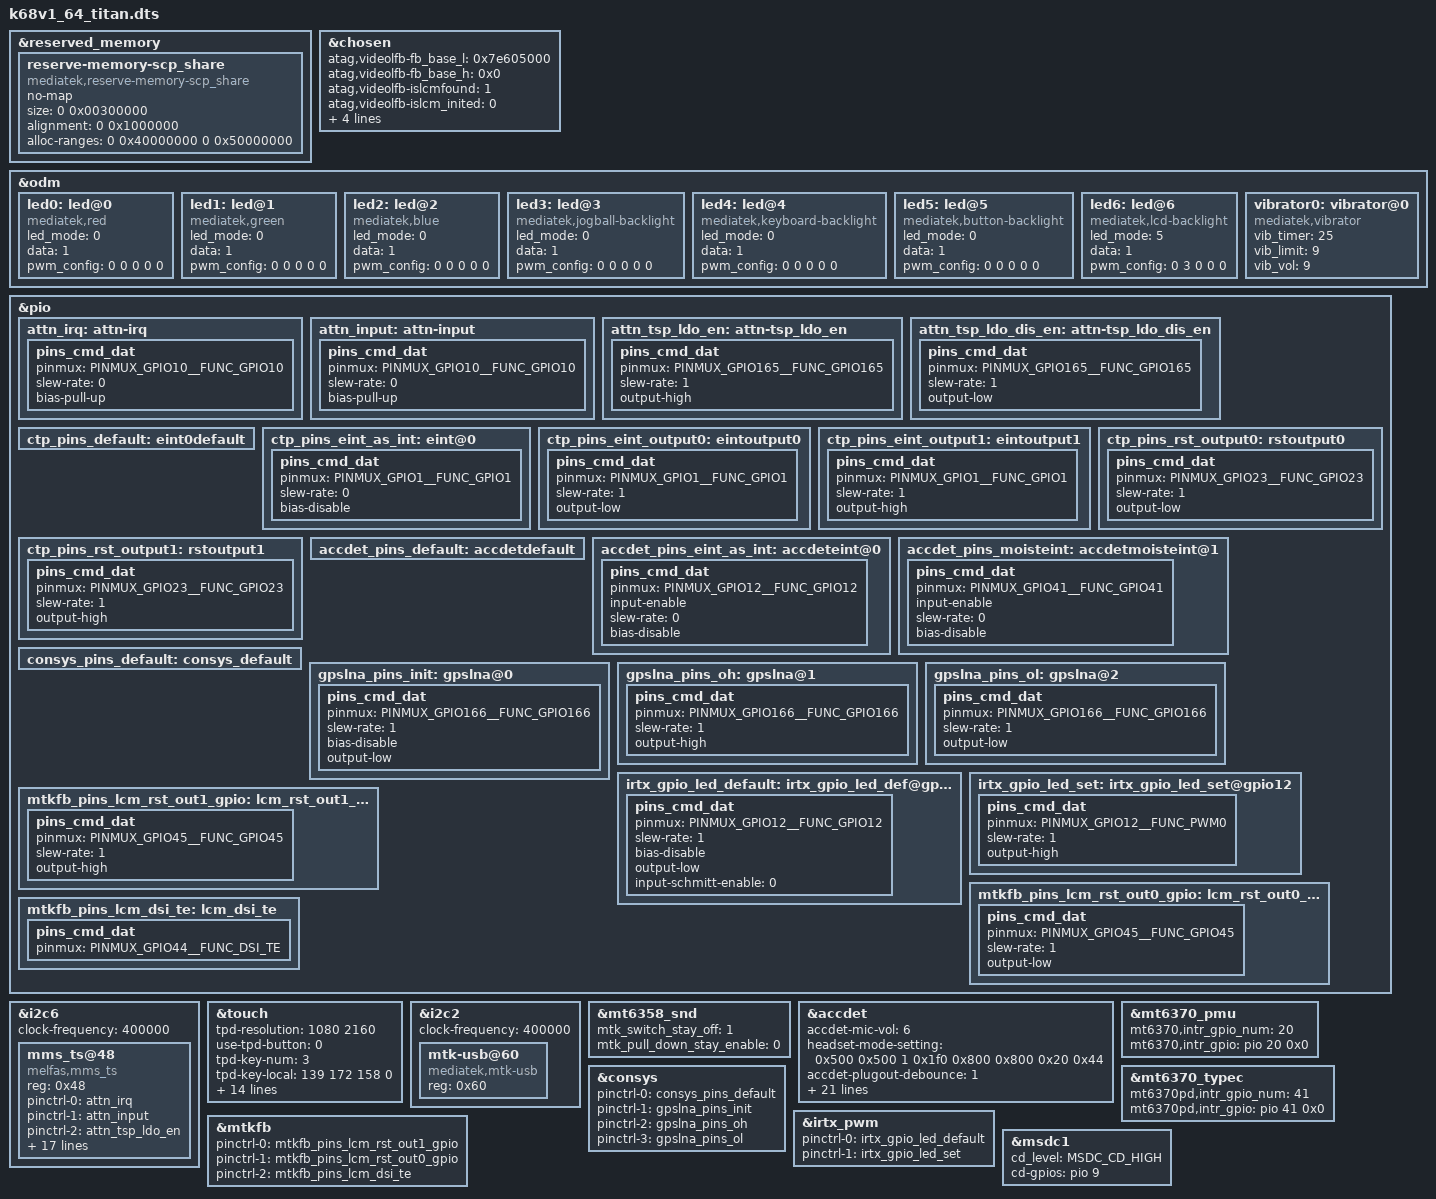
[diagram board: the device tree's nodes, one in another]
/*
 * Copyright (C) 2019 MediaTek Inc.
 *
 * This program is free software; you can redistribute it and/or modify
 * it under the terms of the GNU General Public License version 2 as
 * published by the Free Software Foundation.
 *
 * This program is distributed in the hope that it will be useful,
 * but WITHOUT ANY WARRANTY; without even the implied warranty of
 * MERCHANTABILITY or FITNESS FOR A PARTICULAR PURPOSE.
 * See http://www.gnu.org/licenses/gpl-2.0.html for more details.
 */

#include <dt-bindings/interrupt-controller/irq.h>
#include <dt-bindings/interrupt-controller/arm-gic.h>
#include <dt-bindings/pinctrl/mt6768-pinfunc.h>
#include <dt-bindings/mmc/mt6768-msdc.h>
#include <dt-bindings/gpio/gpio.h>

&reserved_memory {
	reserve-memory-scp_share {
		compatible = "mediatek,reserve-memory-scp_share";
		no-map;
		size = <0 0x00300000>;
		alignment = <0 0x1000000>;
		alloc-ranges = <0 0x40000000 0 0x50000000>;
	};
};

/* chosen */
&chosen {

	atag,videolfb-fb_base_l = <0x7e605000>;
	atag,videolfb-fb_base_h = <0x0>;
	atag,videolfb-islcmfound = <1>;
	atag,videolfb-islcm_inited = <0>;
	atag,videolfb-fps= <6000>;
	atag,videolfb-vramSize= <0x017e8000>;
	atag,videolfb-lcmname=
		"hx83112b_fhdp_dsi_cmd_auo_rt5081_drv";
};

&odm {
	led0:led@0 {
		compatible = "mediatek,red";
		led_mode = <0>;
		data = <1>;
		pwm_config = <0 0 0 0 0>;
	};
	led1:led@1 {
		compatible = "mediatek,green";
		led_mode = <0>;
		data = <1>;
		pwm_config = <0 0 0 0 0>;
	};
	led2:led@2 {
		compatible = "mediatek,blue";
		led_mode = <0>;
		data = <1>;
		pwm_config = <0 0 0 0 0>;
	};
	led3:led@3 {
		compatible = "mediatek,jogball-backlight";
		led_mode = <0>;
		data = <1>;
		pwm_config = <0 0 0 0 0>;
	};
	led4:led@4 {
		compatible = "mediatek,keyboard-backlight";
		led_mode = <0>;
		data = <1>;
		pwm_config = <0 0 0 0 0>;
	};
	led5:led@5 {
		compatible = "mediatek,button-backlight";
		led_mode = <0>;
		data = <1>;
		pwm_config = <0 0 0 0 0>;
	};
	led6:led@6 {
		compatible = "mediatek,lcd-backlight";
		led_mode = <5>;
		data = <1>;
		pwm_config = <0 3 0 0 0>;
	};
	vibrator0:vibrator@0 {
		compatible = "mediatek,vibrator";
		vib_timer = <25>;
		vib_limit = <9>;
		vib_vol= <9>;
	};
};

/* TOUCH start */
/* mms 400 touch */
&pio {
	attn_irq: attn-irq {
		pins_cmd_dat {
			pinmux = <PINMUX_GPIO10__FUNC_GPIO10>;
			slew-rate = <0>;
			bias-pull-up;
			};
	};

	attn_input: attn-input {
		pins_cmd_dat {
			pinmux = <PINMUX_GPIO10__FUNC_GPIO10>;
			slew-rate = <0>;
			bias-pull-up;
		};
	};

	attn_tsp_ldo_en: attn-tsp_ldo_en {
		pins_cmd_dat {
			pinmux = <PINMUX_GPIO165__FUNC_GPIO165>;
			slew-rate = <1>;
			output-high;
		};
	};
	attn_tsp_ldo_dis_en: attn-tsp_ldo_dis_en {
		pins_cmd_dat {
			pinmux = <PINMUX_GPIO165__FUNC_GPIO165>;
			slew-rate = <1>;
			output-low;
		};
	};
};

&i2c6 {
	status = "okay";
	/* samsung,i2c-sda-delay = <100>; */
	/* samsung,i2c-max-bus-freq = <400000>; */
	clock-frequency = <400000>;
	#address-cells = <1>;
	#size-cells = <0>;
	mms_ts@48 {
		compatible = "melfas,mms_ts";
		reg = <0x48>;
		pinctrl-names = "on_state", "off_state",
				"tsp_ldo_en", "tsp_ldo_dis_en";
		pinctrl-0 = <&attn_irq>;
		pinctrl-1 = <&attn_input>;
		pinctrl-2 = <&attn_tsp_ldo_en>;
		pinctrl-3 = <&attn_tsp_ldo_dis_en>;
		/* melfas,vdd_en = "tsp_ldo_en"; */
		/* melfas,io_en = "tsp_io"; */
		melfas,irq-gpio = <&pio 10 0>;
		melfas,scl-gpio = <&pio 89 0>;
		melfas,sda-gpio = <&pio 90 0>;
		/* indicator: 24dp navigator:48dp edge:60px dpi=320 */
		melfas,area-size = <133 266 341>;
		/* x & y */
		melfas,max_x_y = <4095 4095>;
		melfas,node_info = <15 32 0>;
		melfas,event_info = <8 12>;
		melfas,fod_info = <15 14 27>;
		melfas,support_lpm = "true";
		melfas,fw_name = "tsp_melfas/mss100_a50.fw";
		melfas,fw_name_old = "tsp_melfas/mss100_a50_p01.fw";
		melfas,project_name = "A505";
		support_ear_detect_mode;
		enable_settings_aot;
		support_fod;
	};
};

&touch {
	tpd-resolution = <1080 2160>;
	use-tpd-button = <0>;
	tpd-key-num = <3>;
	tpd-key-local= <139 172 158 0>;
	tpd-key-dim-local = <90 883 100 40 230
				883 100 40 370 883 100 40 0 0 0 0>;
	tpd-max-touch-num = <10>;
	tpd-filter-enable = <1>;
	tpd-filter-pixel-density = <168>;
	tpd-filter-custom-prameters = <0 0 0 0 0 0 0 0 0 0 0 0>;
	tpd-filter-custom-speed = <0 0 0>;
	pinctrl-names = "default", "state_eint_as_int",
		"state_eint_output0", "state_eint_output1",
		"state_rst_output0", "state_rst_output1";
	pinctrl-0 = <&ctp_pins_default>;
	pinctrl-1 = <&ctp_pins_eint_as_int>;
	pinctrl-2 = <&ctp_pins_eint_output0>;
	pinctrl-3 = <&ctp_pins_eint_output1>;
	pinctrl-4 = <&ctp_pins_rst_output0>;
	pinctrl-5 = <&ctp_pins_rst_output1>;
	status = "okay";
};
&pio {
	ctp_pins_default: eint0default {
	};
	ctp_pins_eint_as_int: eint@0 {
		pins_cmd_dat {
			pinmux = <PINMUX_GPIO1__FUNC_GPIO1>;
			slew-rate = <0>;
			bias-disable;
		};
	};
	ctp_pins_eint_output0: eintoutput0 {
		pins_cmd_dat {
			pinmux = <PINMUX_GPIO1__FUNC_GPIO1>;
			slew-rate = <1>;
			output-low;
		};
	};
	ctp_pins_eint_output1: eintoutput1 {
		pins_cmd_dat {
			pinmux = <PINMUX_GPIO1__FUNC_GPIO1>;
			slew-rate = <1>;
			output-high;
	};
	};
	ctp_pins_rst_output0: rstoutput0 {
		pins_cmd_dat {
			pinmux = <PINMUX_GPIO23__FUNC_GPIO23>;
			slew-rate = <1>;
			output-low;
		};
	};
	ctp_pins_rst_output1: rstoutput1 {
		pins_cmd_dat {
			pinmux = <PINMUX_GPIO23__FUNC_GPIO23>;
			slew-rate = <1>;
			output-high;
		};
	};
};
/* TOUCH end */

&i2c2 {
	clock-frequency = <400000>;

	mtk-usb@60 {
		compatible = "mediatek,mtk-usb";
		reg = <0x60>;
		status = "okay";
	};
};

/* mt6358 pmic customize setting */
&mt6358_snd {
	mtk_switch_stay_off = <1>;
	mtk_pull_down_stay_enable = <0>;
};

/* accdet start */
&accdet {
	/* accdet micbias voltage: 0x07,2.7v;0x05,2.5v;0x02,1.9v */
	accdet-mic-vol = <6>;
	headset-mode-setting = <0x500 0x500 1 0x1f0 0x800 0x800 0x20 0x44>;
	accdet-plugout-debounce = <1>;
	/*1:ACC mode, 2:low cost without in bias, 6:low cost with in bias*/
	accdet-mic-mode = <1>;
	/* eint_level_trigger: 8,LEVEL_LOW(DEF) ;4,LV_HIGH;others,LV_LOW */
	headset-eint-level-pol = <8>;
	/*min_3pole--max_3pole--min_4pole--max_4pole--vol_bias*/
	headset-vol-threshold = <0 590 591 1680 2600>;
	/*0--MD_MAX--UP_MAX--DW_MAX*/
	headset-three-key-threshold = <0 80 220 400>;
	headset-three-key-threshold-CDD = <0 121 192 600>;
	/*0--MD_MAX--VOICE_MAX--UP_MAX--DW_MAX*/
	headset-four-key-threshold = <0 58 121 192 400>;

	/* moisture SW mode config start, use external resister or not.
	 */
	moisture-plug-in-threshold = <0 514 749>;
	moisture_use_ext_res = <1>;
	/* moisture of water resister ohm, SW mode by auxadc*/
	moisture-water-r = <50000>;
	/* moisture SW mode config end */

	/* ACCDET GPIO standardization for AP EINT */
	pinctrl-names = "default", "state_eint_as_int", "state_moisteint";
	pinctrl-0 = <&accdet_pins_default>;
	pinctrl-1 = <&accdet_pins_eint_as_int>;
	pinctrl-2 = <&accdet_pins_moisteint>;
	interrupt-parent = <&pio>;
	interrupts = <12 IRQ_TYPE_LEVEL_LOW 12 0x0>,
			<41 IRQ_TYPE_LEVEL_LOW 41 0x0>;
	deb-gpios = <&pio 12 0>;
	plugin-debounce = <640000>;
	plugout-debounce = <625>;
	moist-deb-gpios = <&pio 41 0>;
	moist-plugin-debounce = <128>;
	moist-plugout-debounce = <1000>;
	status = "okay";
};
&pio {
	accdet_pins_default: accdetdefault {
	};
	accdet_pins_eint_as_int: accdeteint@0 {
		pins_cmd_dat {
			pinmux = <PINMUX_GPIO12__FUNC_GPIO12>;
			input-enable;
			slew-rate = <0>;
			bias-disable;
		};
	};
	accdet_pins_moisteint: accdetmoisteint@1 {
		pins_cmd_dat {
			pinmux = <PINMUX_GPIO41__FUNC_GPIO41>;
			input-enable;
			slew-rate = <0>;
			bias-disable;
		};
	};
};
/* accdet end */


&mt6370_pmu {
	mt6370,intr_gpio_num = <20>; /* direct defined GPIO num */
	mt6370,intr_gpio = <&pio 20 0x0>;
};
&mt6370_typec {
	mt6370pd,intr_gpio_num = <41>; /* direct defined GPIO num */
	mt6370pd,intr_gpio = <&pio 41 0x0>;
};

/* CONSYS GPIO standardization */
&pio {
	consys_pins_default: consys_default {
	};
	gpslna_pins_init: gpslna@0 {
		pins_cmd_dat {
			pinmux = <PINMUX_GPIO166__FUNC_GPIO166>;
			slew-rate = <1>;
			bias-disable;
			output-low;
		};
	};
	gpslna_pins_oh: gpslna@1 {
		pins_cmd_dat {
			pinmux = <PINMUX_GPIO166__FUNC_GPIO166>;
			slew-rate = <1>;
			output-high;
		};
	};
	gpslna_pins_ol: gpslna@2 {
		pins_cmd_dat {
			pinmux = <PINMUX_GPIO166__FUNC_GPIO166>;
			slew-rate = <1>;
			output-low;
		};
	};
};
&consys {
	pinctrl-names = "default", "gps_lna_state_init",
		"gps_lna_state_oh", "gps_lna_state_ol";
	pinctrl-0 = <&consys_pins_default>;
	pinctrl-1 = <&gpslna_pins_init>;
	pinctrl-2 = <&gpslna_pins_oh>;
	pinctrl-3 = <&gpslna_pins_ol>;
	status = "okay";
};
/* CONSYS end */

/* IRTX GPIO Start */
&irtx_pwm {
	pinctrl-names = "irtx_gpio_led_default", "irtx_gpio_led_set";
	pinctrl-0 = <&irtx_gpio_led_default>;
	pinctrl-1 = <&irtx_gpio_led_set>;
	status = "okay";
};
&pio {
	/* IRTX GPIO Settings -Start */
	/* default: GPIO0, output, high */
	irtx_gpio_led_default:irtx_gpio_led_def@gpio12 {
		pins_cmd_dat {
			pinmux = <PINMUX_GPIO12__FUNC_GPIO12>;
			slew-rate = <1>;
			bias-disable;
			output-low;
			input-schmitt-enable = <0>;
		};
	};

	irtx_gpio_led_set:irtx_gpio_led_set@gpio12 {
		pins_cmd_dat {
			pinmux = <PINMUX_GPIO12__FUNC_PWM0>;
			slew-rate = <1>;
			output-high;
		};
	};
}; /* IRTX GPIO Settings -End */

/* DISPSYS GPIO standardization */
&pio {
	mtkfb_pins_lcm_rst_out1_gpio: lcm_rst_out1_gpio {
		pins_cmd_dat {
			pinmux = <PINMUX_GPIO45__FUNC_GPIO45>;
			slew-rate = <1>;
			output-high;
		};
	};

	mtkfb_pins_lcm_rst_out0_gpio: lcm_rst_out0_gpio {
		pins_cmd_dat {
			pinmux = <PINMUX_GPIO45__FUNC_GPIO45>;
			slew-rate = <1>;
			output-low;
		};
	};

	mtkfb_pins_lcm_dsi_te: lcm_dsi_te {
		pins_cmd_dat {
			pinmux = <PINMUX_GPIO44__FUNC_DSI_TE>;
		};
	};
};

&mtkfb {
	pinctrl-names =
		"lcm_rst_out1_gpio", "lcm_rst_out0_gpio",
		"mode_te_te";
	pinctrl-0 = <&mtkfb_pins_lcm_rst_out1_gpio>;
	pinctrl-1 = <&mtkfb_pins_lcm_rst_out0_gpio>;
	pinctrl-2 = <&mtkfb_pins_lcm_dsi_te>;
	status = "okay";
};

/* DISPSYS GPIO standardization end*/

&msdc1 {
	cd_level = /bits/ 8 <MSDC_CD_HIGH>;
	cd-gpios = <&pio 9 0>;
};

//#include <k68v1_64_titan/cust.dtsi>
//#include "mediatek/cust_mt6768_camera.dtsi"
//#include "mediatek/cust_mt6768_touch_1080x2160.dtsi"
/*End of this file, DO NOT ADD ANYTHING HERE*/
